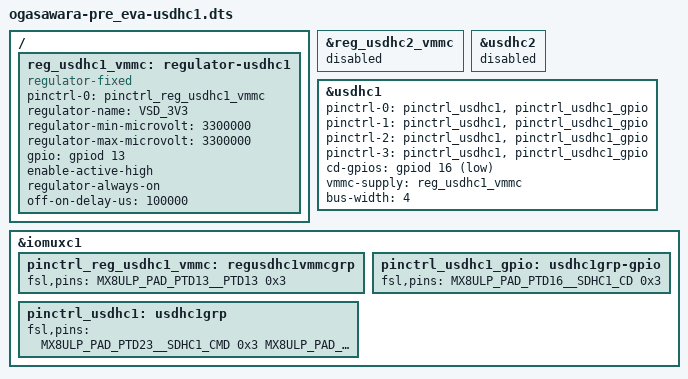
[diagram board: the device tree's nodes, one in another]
// SPDX-License-Identifier: (GPL-2.0 OR MIT)
/*
 * Copyright (C) 2021 Atmark Techno, Inc. All Rights Reserved.
 */

/dts-v1/;

#include "ogasawara-pre_eva.dts"

&reg_usdhc2_vmmc {
	status = "disabled";
};

&usdhc2 {
	status = "disabled";
};

/{
	reg_usdhc1_vmmc: regulator-usdhc1 {
		compatible = "regulator-fixed";
		pinctrl-names = "default";
		pinctrl-0 = <&pinctrl_reg_usdhc1_vmmc>;
		regulator-name = "VSD_3V3";
		regulator-min-microvolt = <3300000>;
		regulator-max-microvolt = <3300000>;
		gpio = <&gpiod 13 GPIO_ACTIVE_HIGH>;
		enable-active-high;
		regulator-always-on;
		off-on-delay-us = <100000>;
	};
};

// SD card
&usdhc1 {
	pinctrl-names = "default", "state_100mhz", "state_200mhz", "sleep";
	pinctrl-0 = <&pinctrl_usdhc1>, <&pinctrl_usdhc1_gpio>;
	pinctrl-1 = <&pinctrl_usdhc1>, <&pinctrl_usdhc1_gpio>;
	pinctrl-2 = <&pinctrl_usdhc1>, <&pinctrl_usdhc1_gpio>;
	pinctrl-3 = <&pinctrl_usdhc1>, <&pinctrl_usdhc1_gpio>;
	cd-gpios = <&gpiod 16 GPIO_ACTIVE_LOW>;
	vmmc-supply = <&reg_usdhc1_vmmc>;
	bus-width = <4>;
	status = "okay";
};

&iomuxc1 {
	pinctrl_reg_usdhc1_vmmc: regusdhc1vmmcgrp {
		fsl,pins = <
			MX8ULP_PAD_PTD13__PTD13		0x3
		>;
	};

	pinctrl_usdhc1_gpio: usdhc1grp-gpio {
		fsl,pins = <
			MX8ULP_PAD_PTD16__SDHC1_CD	0x3
		>;
	};

	pinctrl_usdhc1: usdhc1grp {
		fsl,pins = <
			MX8ULP_PAD_PTD23__SDHC1_CMD	0x3
			MX8ULP_PAD_PTD22__SDHC1_CLK	0x10002
			MX8ULP_PAD_PTD21__SDHC1_D0	0x3
			MX8ULP_PAD_PTD20__SDHC1_D1	0x3
			MX8ULP_PAD_PTD19__SDHC1_D2	0x3
			MX8ULP_PAD_PTD18__SDHC1_D3	0x3
			MX8ULP_PAD_PTD15__SDHC1_VS	0x3
		>;
	};
};
